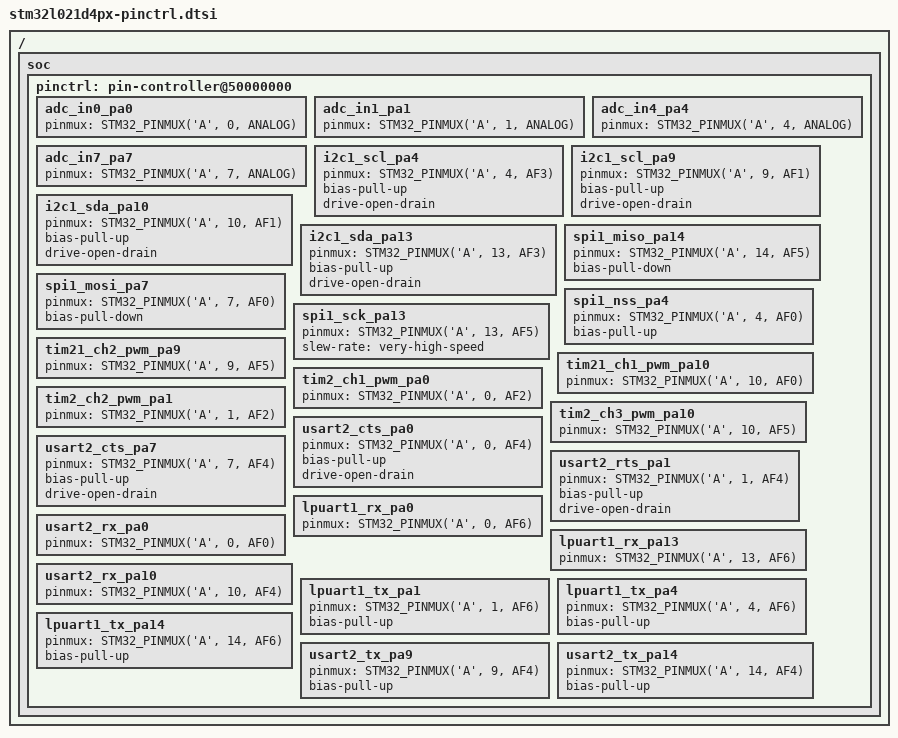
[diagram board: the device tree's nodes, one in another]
/*
 * NOTE: Autogenerated file using genpinctrl.py
 *
 * SPDX-License-Identifier: Apache-2.0
 */

#include <dt-bindings/pinctrl/stm32-pinctrl.h>

/ {
	soc {
		pinctrl: pin-controller@50000000 {

			/* ADC_IN / ADC_INN / ADC_INP */

			adc_in0_pa0: adc_in0_pa0 {
				pinmux = <STM32_PINMUX('A', 0, ANALOG)>;
			};

			adc_in1_pa1: adc_in1_pa1 {
				pinmux = <STM32_PINMUX('A', 1, ANALOG)>;
			};

			adc_in4_pa4: adc_in4_pa4 {
				pinmux = <STM32_PINMUX('A', 4, ANALOG)>;
			};

			adc_in7_pa7: adc_in7_pa7 {
				pinmux = <STM32_PINMUX('A', 7, ANALOG)>;
			};

			/* I2C_SCL */

			i2c1_scl_pa4: i2c1_scl_pa4 {
				pinmux = <STM32_PINMUX('A', 4, AF3)>;
				bias-pull-up;
				drive-open-drain;
			};

			i2c1_scl_pa9: i2c1_scl_pa9 {
				pinmux = <STM32_PINMUX('A', 9, AF1)>;
				bias-pull-up;
				drive-open-drain;
			};

			/* I2C_SDA */

			i2c1_sda_pa10: i2c1_sda_pa10 {
				pinmux = <STM32_PINMUX('A', 10, AF1)>;
				bias-pull-up;
				drive-open-drain;
			};

			i2c1_sda_pa13: i2c1_sda_pa13 {
				pinmux = <STM32_PINMUX('A', 13, AF3)>;
				bias-pull-up;
				drive-open-drain;
			};

			/* SPI_MISO */

			spi1_miso_pa14: spi1_miso_pa14 {
				pinmux = <STM32_PINMUX('A', 14, AF5)>;
				bias-pull-down;
			};

			/* SPI_MOSI */

			spi1_mosi_pa7: spi1_mosi_pa7 {
				pinmux = <STM32_PINMUX('A', 7, AF0)>;
				bias-pull-down;
			};

			/* SPI_NSS */

			spi1_nss_pa4: spi1_nss_pa4 {
				pinmux = <STM32_PINMUX('A', 4, AF0)>;
				bias-pull-up;
			};

			/* SPI_SCK */

			spi1_sck_pa13: spi1_sck_pa13 {
				pinmux = <STM32_PINMUX('A', 13, AF5)>;
				slew-rate = "very-high-speed";
			};

			/* TIM_CH_PWM / TIM_CHN_PWM */

			tim21_ch2_pwm_pa9: tim21_ch2_pwm_pa9 {
				pinmux = <STM32_PINMUX('A', 9, AF5)>;
			};

			tim21_ch1_pwm_pa10: tim21_ch1_pwm_pa10 {
				pinmux = <STM32_PINMUX('A', 10, AF0)>;
			};

			tim2_ch1_pwm_pa0: tim2_ch1_pwm_pa0 {
				pinmux = <STM32_PINMUX('A', 0, AF2)>;
			};

			tim2_ch2_pwm_pa1: tim2_ch2_pwm_pa1 {
				pinmux = <STM32_PINMUX('A', 1, AF2)>;
			};

			tim2_ch3_pwm_pa10: tim2_ch3_pwm_pa10 {
				pinmux = <STM32_PINMUX('A', 10, AF5)>;
			};

			/* UART_CTS / USART_CTS / LPUART_CTS */

			usart2_cts_pa0: usart2_cts_pa0 {
				pinmux = <STM32_PINMUX('A', 0, AF4)>;
				bias-pull-up;
				drive-open-drain;
			};

			usart2_cts_pa7: usart2_cts_pa7 {
				pinmux = <STM32_PINMUX('A', 7, AF4)>;
				bias-pull-up;
				drive-open-drain;
			};

			/* UART_RTS / USART_RTS / LPUART_RTS */

			usart2_rts_pa1: usart2_rts_pa1 {
				pinmux = <STM32_PINMUX('A', 1, AF4)>;
				bias-pull-up;
				drive-open-drain;
			};

			/* UART_RX / USART_RX / LPUART_RX */

			lpuart1_rx_pa0: lpuart1_rx_pa0 {
				pinmux = <STM32_PINMUX('A', 0, AF6)>;
			};

			lpuart1_rx_pa13: lpuart1_rx_pa13 {
				pinmux = <STM32_PINMUX('A', 13, AF6)>;
			};

			usart2_rx_pa0: usart2_rx_pa0 {
				pinmux = <STM32_PINMUX('A', 0, AF0)>;
			};

			usart2_rx_pa10: usart2_rx_pa10 {
				pinmux = <STM32_PINMUX('A', 10, AF4)>;
			};

			/* UART_TX / USART_TX / LPUART_TX */

			lpuart1_tx_pa1: lpuart1_tx_pa1 {
				pinmux = <STM32_PINMUX('A', 1, AF6)>;
				bias-pull-up;
			};

			lpuart1_tx_pa4: lpuart1_tx_pa4 {
				pinmux = <STM32_PINMUX('A', 4, AF6)>;
				bias-pull-up;
			};

			lpuart1_tx_pa14: lpuart1_tx_pa14 {
				pinmux = <STM32_PINMUX('A', 14, AF6)>;
				bias-pull-up;
			};

			usart2_tx_pa9: usart2_tx_pa9 {
				pinmux = <STM32_PINMUX('A', 9, AF4)>;
				bias-pull-up;
			};

			usart2_tx_pa14: usart2_tx_pa14 {
				pinmux = <STM32_PINMUX('A', 14, AF4)>;
				bias-pull-up;
			};

		};
	};
};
